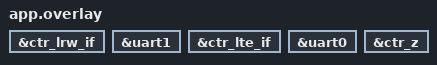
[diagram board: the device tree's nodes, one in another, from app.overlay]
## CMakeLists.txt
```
#
# Copyright (c) 2024 HARDWARIO a.s.
#
#  SPDX-License-Identifier: LicenseRef-HARDWARIO-5-Clause
#

cmake_minimum_required(VERSION 3.20.0)

set(ENV{FW_BUNDLE} "com.hardwario.chester.push")
set(ENV{FW_VERSION} "v1.0.0")
set(ENV{FW_NAME} "CHESTER Push")

find_package(Zephyr REQUIRED HINTS $ENV{ZEPHYR_BASE})

project(chester-push)

add_custom_command(
    COMMAND ../../../scripts/gen-msg-key.py ../codec/cbor-decoder.yaml ../src/msg_key.h
    OUTPUT ../src/msg_key.h
    MAIN_DEPENDENCY ../codec/cbor-decoder.yaml
)

target_sources(app PRIVATE src/app_sensor.c)
target_sources(app PRIVATE src/main.c)
target_sources(app PRIVATE src/app_shell.c)
target_sources(app PRIVATE src/app_init.c)
target_sources(app PRIVATE src/app_data.c)
target_sources(app PRIVATE src/app_power.c)
target_sources(app PRIVATE src/app_send.c)
target_sources(app PRIVATE src/app_config.c)
target_sources(app PRIVATE src/app_work.c)
target_sources(app PRIVATE src/app_handler.c)
target_sources(app PRIVATE src/app_backup.c)
target_sources(app PRIVATE src/app_cbor.c)
```

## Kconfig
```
#
# Copyright (c) 2024 HARDWARIO a.s.
#
# SPDX-License-Identifier: LicenseRef-HARDWARIO-5-Clause
#

menu "Application"

# CHESTER PUSH Project | PUSH Variant 

# LRW 
config SHIELD_CTR_LRW
	bool "Enable SHIELD_CTR_LRW"
	default y 

config CTR_LRW
	default y
# LTE 
config SHIELD_CTR_LTE
	bool "Enable SHIELD_CTR_LTE"
	default y 

config CTR_LTE
	default y
# Z 
config SHIELD_CTR_Z
	bool "Enable SHIELD_CTR_Z"
	default y 

config CTR_Z
	default y

config I2C
	default y

endmenu

menu "Zephyr Kernel"
source "Kconfig.zephyr"
endmenu
```

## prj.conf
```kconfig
#
# Copyright (c) 2024 HARDWARIO a.s.
#
#  SPDX-License-Identifier: LicenseRef-HARDWARIO-5-Clause
#

# Configurations
CONFIG_ADC_SHELL=y
CONFIG_CTR_ACCEL=y
CONFIG_CTR_ADC=y
CONFIG_CTR_BATT=y
CONFIG_CTR_BUTTON=y
CONFIG_CTR_BLE=y
CONFIG_CTR_BUF=y
CONFIG_CTR_DEFAULTS=y
CONFIG_CTR_EDGE=y
CONFIG_CTR_INFO=y
CONFIG_CTR_LED=y
CONFIG_CTR_LOG=y
CONFIG_CTR_RTC=y
CONFIG_CTR_THERM=y
CONFIG_CTR_WDOG=y
CONFIG_ENTROPY_GENERATOR=y
CONFIG_TINYCRYPT=y
CONFIG_TINYCRYPT_SHA256=y
CONFIG_ZCBOR=y
CONFIG_ZCBOR_STOP_ON_ERROR=y
CONFIG_CTR_LTE_CLKSYNC=y

# Extra configurations
CONFIG_ADC_TLA2021_INIT_PRIORITY=60
CONFIG_ADC_SHELL=n
CONFIG_ADC_NRFX_SAADC=n

# USER CODE BEGIN Config 
# USER CODE END Config
```

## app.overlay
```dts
/*
 * Copyright (c) 2024 HARDWARIO a.s.
 *
 * SPDX-License-Identifier: LicenseRef-HARDWARIO-5-Clause
 */

/* CHESTER PUSH Project | PUSH Variant */

/* LRW   */
&ctr_lrw_if {
	status = "okay";
};

&uart1 {
	status = "okay";
};
/* LTE  */
&ctr_lte_if {
	status = "okay";
};

&uart0 {
	status = "okay";
};
/* Z  */
&ctr_z {
	status = "okay";
};
```

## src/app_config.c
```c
/*
 * Copyright (c) 2024 HARDWARIO a.s.
 *
 * SPDX-License-Identifier: LicenseRef-HARDWARIO-5-Clause
 */

#include "app_config.h"

/* CHESTER includes */
#include <chester/ctr_config.h>

/* Zephyr includes */
#include <zephyr/init.h>
#include <zephyr/kernel.h>
#include <zephyr/logging/log.h>
#include <zephyr/settings/settings.h>
#include <zephyr/shell/shell.h>

/* Standard includes */
#include <ctype.h>
#include <stdbool.h>
#include <stdio.h>
#include <stdlib.h>
#include <string.h>

/* USER CODE BEGIN Includes */
/* USER CODE END Includes */

LOG_MODULE_REGISTER(app_config, LOG_LEVEL_DBG);

#define SETTINGS_PFX "chester-push"

struct app_config g_app_config;

static struct app_config m_app_config_interim = {
	.interval_report = 1800,
	.interval_sample = 60,
	.event_report_delay = 5,
	.event_report_rate = 30,
	.backup_report_connected = true,
	.backup_report_disconnected = true,
	.mode = APP_CONFIG_MODE_LTE,

	/* USER CODE BEGIN Struct Variables */
	/* USER CODE END Struct Variables */
};

/* USER CODE BEGIN Variables */
/* USER CODE END Variables */

static void print_app_config_mode(const struct shell *shell)
{
	const char *mode;
	switch (m_app_config_interim.mode) {
	case APP_CONFIG_MODE_NONE:
		mode = "none";
		break;
	case APP_CONFIG_MODE_LTE:
		mode = "lte";
		break;
	case APP_CONFIG_MODE_LRW:
		mode = "lrw";
		break;
	default:
		mode = "(unknown)";
		break;
	}

	shell_print(shell, "app config mode %s", mode);
}

int app_config_cmd_config_mode(const struct shell *shell, size_t argc, char **argv)
{
	if (argc == 1) {
		print_app_config_mode(shell);
		return 0;
	}

	if (argc == 2) {
		if (!strcmp("none", argv[1])) {
			m_app_config_interim.mode = APP_CONFIG_MODE_NONE;
			return 0;
		}

		if (!strcmp("lte", argv[1])) {
			m_app_config_interim.mode = APP_CONFIG_MODE_LTE;
			return 0;
		}

		if (!strcmp("lrw", argv[1])) {
			m_app_config_interim.mode = APP_CONFIG_MODE_LRW;
			return 0;
		}

		shell_error(shell, "invalid option");

		return -EINVAL;
	}

	shell_help(shell);

	return -EINVAL;
}

static void print_interval_report(const struct shell *shell)
{
	shell_print(shell, "app config interval-report  %d",
			m_app_config_interim.interval_report);
}

int app_config_cmd_config_interval_report(const struct shell *shell, size_t argc, char **argv)
{
	if (argc == 1) {
		print_interval_report(shell);
		return 0;
	}
	if (argc == 2) {
		size_t len = strlen(argv[1]);
		for (size_t i = 0; i < len; i++) {
			if (!isdigit((int)argv[1][i])) {
				shell_error(shell, "invalid format");
				return -EINVAL;
			}
		}
		long value = strtol(argv[1], NULL, 10);
		if (value < 30 || value > 86400) {
			shell_error(shell, "invalid range");
			return -EINVAL;
		}
		m_app_config_interim.interval_report = (int)value;
		return 0;
	}
	shell_help(shell);
	return -EINVAL;
}

static void print_interval_sample(const struct shell *shell)
{
	shell_print(shell, "app config interval-sample  %d",
			m_app_config_interim.interval_sample);
}

int app_config_cmd_config_interval_sample(const struct shell *shell, size_t argc, char **argv)
{
	if (argc == 1) {
		print_interval_sample(shell);
		return 0;
	}
	if (argc == 2) {
		size_t len = strlen(argv[1]);
		for (size_t i = 0; i < len; i++) {
			if (!isdigit((int)argv[1][i])) {
				shell_error(shell, "invalid format");
				return -EINVAL;
			}
		}
		long value = strtol(argv[1], NULL, 10);
		if (value < 1 || value > 86400) {
			shell_error(shell, "invalid range");
			return -EINVAL;
		}
		m_app_config_interim.interval_sample = (int)value;
		return 0;
	}
	shell_help(shell);
	return -EINVAL;
}

static void print_event_report_delay(const struct shell *shell)
{
	shell_print(shell, "app config event-report-delay  %d",
			m_app_config_interim.event_report_delay);
}

int app_config_cmd_config_event_report_delay(const struct shell *shell, size_t argc, char **argv)
{
	if (argc == 1) {
		print_event_report_delay(shell);
		return 0;
	}
	if (argc == 2) {
		size_t len = strlen(argv[1]);
		for (size_t i = 0; i < len; i++) {
			if (!isdigit((int)argv[1][i])) {
				shell_error(shell, "invalid format");
				return -EINVAL;
			}
		}
		long value = strtol(argv[1], NULL, 10);
		if (value < 1 || value > 86400) {
			shell_error(shell, "invalid range");
			return -EINVAL;
		}
		m_app_config_interim.event_report_delay = (int)value;
		return 0;
	}
	shell_help(shell);
	return -EINVAL;
}

static void print_event_report_rate(const struct shell *shell)
{
	shell_print(shell, "app config event-report-rate  %d",
			m_app_config_interim.event_report_rate);
}

int app_config_cmd_config_event_report_rate(const struct shell *shell, size_t argc, char **argv)
{
	if (argc == 1) {
		print_event_report_rate(shell);
		return 0;
	}
	if (argc == 2) {
		size_t len = strlen(argv[1]);
		for (size_t i = 0; i < len; i++) {
			if (!isdigit((int)argv[1][i])) {
				shell_error(shell, "invalid format");
				return -EINVAL;
			}
		}
		long value = strtol(argv[1], NULL, 10);
		if (value < 1 || value > 3600) {
			shell_error(shell, "invalid range");
			return -EINVAL;
		}
		m_app_config_interim.event_report_rate = (int)value;
		return 0;
	}
	shell_help(shell);
	return -EINVAL;
}

static void print_backup_report_connected(const struct shell *shell)
{
	shell_print(shell, "app config backup-report-connected  %s",
			m_app_config_interim.backup_report_connected ? "true" : "false");
}

int app_config_cmd_config_backup_report_connected(const struct shell *shell, size_t argc, char **argv)
{
	if (argc == 1) {
		print_backup_report_connected(shell);                                                    
		return 0;
	}
	if (argc == 2) {
		bool is_false = !strcmp(argv[1], "false");
		bool is_true = !strcmp(argv[1], "true");
		if (is_false) {
			m_app_config_interim.backup_report_connected = false;
		} else if (is_true) {
			m_app_config_interim.backup_report_connected = true;
		} else {
			shell_error(shell, "invalid format");
			return -EINVAL;
		}
		return 0;
	}
	shell_help(shell);
	return -EINVAL;
}

static void print_backup_report_disconnected(const struct shell *shell)
{
	shell_print(shell, "app config backup-report-disconnected  %s",
			m_app_config_interim.backup_report_disconnected ? "true" : "false");
}

int app_config_cmd_config_backup_report_disconnected(const struct shell *shell, size_t argc, char **argv)
{
	if (argc == 1) {
		print_backup_report_disconnected(shell);                                                    
		return 0;
	}
	if (argc == 2) {
		bool is_false = !strcmp(argv[1], "false");
		bool is_true = !strcmp(argv[1], "true");
		if (is_false) {
			m_app_config_interim.backup_report_disconnected = false;
		} else if (is_true) {
			m_app_config_interim.backup_report_disconnected = true;
		} else {
			shell_error(shell, "invalid format");
			return -EINVAL;
		}
		return 0;
	}
	shell_help(shell);
	return -EINVAL;
}

int app_config_cmd_config_show(const struct shell *shell, size_t argc, char **argv)
{
	print_app_config_mode(shell);
	print_interval_report(shell);
	print_interval_sample(shell);
	print_event_report_delay(shell);
	print_event_report_rate(shell);
	print_backup_report_connected(shell);
	print_backup_report_disconnected(shell);
	
	return 0;
}

/* USER CODE BEGIN Functions 1 */
/* USER CODE END Functions 1 */

static int h_commit(void)
{
	LOG_DBG("Loaded settings in full");
	memcpy(&g_app_config, &m_app_config_interim, sizeof(g_app_config));

	return 0;
}

static int h_set(const char *key, size_t len, settings_read_cb read_cb, void *cb_arg) 
{
	int ret;
	const char *next;
	if (settings_name_steq(key, "mode", &next) && !next) {
		if (len != sizeof(m_app_config_interim.mode)) {
			return -EINVAL;
		}
		ret = read_cb(cb_arg, &m_app_config_interim.mode, len);
		if (ret < 0) {
			LOG_ERR("Call `read_cb` failed: %d", ret);
			return ret;
		}
		return 0;
	}
	
	if (settings_name_steq(key, "interval-report", &next) && !next) {
		if (len != sizeof(m_app_config_interim.interval_report)) {
			return -EINVAL;
		}
		ret = read_cb(cb_arg, &m_app_config_interim.interval_report, len);
		if (ret < 0) {
			LOG_ERR("Call `read_cb` failed: %d", ret);
			return ret;
		}
		return 0;
	}

	if (settings_name_steq(key, "interval-sample", &next) && !next) {
		if (len != sizeof(m_app_config_interim.interval_sample)) {
			return -EINVAL;
		}
		ret = read_cb(cb_arg, &m_app_config_interim.interval_sample, len);
		if (ret < 0) {
			LOG_ERR("Call `read_cb` failed: %d", ret);
			return ret;
		}
		return 0;
	}

	if (settings_name_steq(key, "event-report-delay", &next) && !next) {
		if (len != sizeof(m_app_config_interim.event_report_delay)) {
			return -EINVAL;
		}
		ret = read_cb(cb_arg, &m_app_config_interim.event_report_delay, len);
		if (ret < 0) {
			LOG_ERR("Call `read_cb` failed: %d", ret);
			return ret;
		}
		return 0;
	}

	if (settings_name_steq(key, "event-report-rate", &next) && !next) {
		if (len != sizeof(m_app_config_interim.event_report_rate)) {
			return -EINVAL;
		}
		ret = read_cb(cb_arg, &m_app_config_interim.event_report_rate, len);
		if (ret < 0) {
			LOG_ERR("Call `read_cb` failed: %d", ret);
			return ret;
		}
		return 0;
	}

	if (settings_name_steq(key, "backup-report-connected", &next) && !next) {
		if (len != sizeof(m_app_config_interim.backup_report_connected)) {
			return -EINVAL;
		}
		ret = read_cb(cb_arg, &m_app_config_interim.backup_report_connected, len);
		if (ret < 0) {
			LOG_ERR("Call `read_cb` failed: %d", ret);
			return ret;
		}
		return 0;
	}

	if (settings_name_steq(key, "backup-report-disconnected", &next) && !next) {
		if (len != sizeof(m_app_config_interim.backup_report_disconnected)) {
			return -EINVAL;
		}
		ret = read_cb(cb_arg, &m_app_config_interim.backup_report_disconnected, len);
		if (ret < 0) {
			LOG_ERR("Call `read_cb` failed: %d", ret);
			return ret;
		}
		return 0;
	}

	/* USER CODE BEGIN Functions 2 */
	/* USER CODE END Functions 2 */

	return 0;
}

static int h_export(int (*export_func)(const char *name, const void *val, size_t val_len))
{
	int ret;
	ret = export_func("chester-push/mode", &m_app_config_interim.mode,
					  sizeof( m_app_config_interim.mode));
	if (ret < 0) {
		return ret;
	}

	ret = export_func("chester-push/interval-report", &m_app_config_interim.interval_report,
					  sizeof( m_app_config_interim.interval_report));
	if (ret < 0) {
		return ret;
	}

	ret = export_func("chester-push/interval-sample", &m_app_config_interim.interval_sample,
					  sizeof( m_app_config_interim.interval_sample));
	if (ret < 0) {
		return ret;
	}

	ret = export_func("chester-push/event-report-delay", &m_app_config_interim.event_report_delay,
					  sizeof( m_app_config_interim.event_report_delay));
	if (ret < 0) {
		return ret;
	}

	ret = export_func("chester-push/event-report-rate", &m_app_config_interim.event_report_rate,
					  sizeof( m_app_config_interim.event_report_rate));
	if (ret < 0) {
		return ret;
	}

	ret = export_func("chester-push/backup-report-connected", &m_app_config_interim.backup_report_connected,
					  sizeof( m_app_config_interim.backup_report_connected));
	if (ret < 0) {
		return ret;
	}

	ret = export_func("chester-push/backup-report-disconnected", &m_app_config_interim.backup_report_disconnected,
					  sizeof( m_app_config_interim.backup_report_disconnected));
	if (ret < 0) {
		return ret;
	}

	/* USER CODE BEGIN Functions 3 */
	/* USER CODE END Functions 3 */

	return 0;
}

static int init(void) 
{
	int ret;

	LOG_INF("System initialization");

	static struct settings_handler sh = {
		.name = SETTINGS_PFX,
		.h_set = h_set,
		.h_commit = h_commit,
		.h_export = h_export,
	};

	ret = settings_register(&sh);

	if (ret < 0) {
		LOG_ERR("Call `settings_register` failed: %d", ret);
		return ret;
	}

	ret = settings_load_subtree(SETTINGS_PFX);

	if (ret < 0) {
		LOG_ERR("Call `settings_load_subtree` failed: %d", ret);
		return ret;
	}

	ctr_config_append_show(SETTINGS_PFX, app_config_cmd_config_show);

	/* USER CODE BEGIN Functions 4 */
	/* USER CODE END Functions 4 */

	return 0;
}

SYS_INIT(init, APPLICATION, CONFIG_APPLICATION_INIT_PRIORITY);
```

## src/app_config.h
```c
/*
 * Copyright (c) 2024 HARDWARIO a.s.
 *
 * SPDX-License-Identifier: LicenseRef-HARDWARIO-5-Clause
 */

#ifndef APP_CONFIG_H_
#define APP_CONFIG_H_

/* Zephyr includes */
#include <zephyr/shell/shell.h>

/* Standard includes */
#include <stdbool.h>
#include <stddef.h>

/* USER CODE BEGIN Includes */
/* USER CODE END Includes */

#ifdef __cplusplus
extern "C" {
#endif

enum app_config_mode {
	APP_CONFIG_MODE_NONE = 0,
	APP_CONFIG_MODE_LTE = 1,
	APP_CONFIG_MODE_LRW = 2,
};

struct app_config {
	enum app_config_mode mode;
	int interval_report;
	int interval_sample;
	int event_report_delay;
	int event_report_rate;
	bool backup_report_connected;
	bool backup_report_disconnected;

	/* USER CODE BEGIN Struct Variables */
	/* USER CODE END Struct Variables */
};

extern struct app_config g_app_config;

/* USER CODE BEGIN Variables */
/* USER CODE END Variables */

int app_config_cmd_config_mode(const struct shell *shell, size_t argc, char **argv);
int app_config_cmd_config_show(const struct shell *shell, size_t argc, char **argv);
int app_config_cmd_config_interval_report(const struct shell *shell, size_t argc, char **argv);
int app_config_cmd_config_interval_sample(const struct shell *shell, size_t argc, char **argv);
int app_config_cmd_config_event_report_delay(const struct shell *shell, size_t argc, char **argv);
int app_config_cmd_config_event_report_rate(const struct shell *shell, size_t argc, char **argv);
int app_config_cmd_config_backup_report_connected(const struct shell *shell, size_t argc, char **argv);
int app_config_cmd_config_backup_report_disconnected(const struct shell *shell, size_t argc, char **argv);

/* USER CODE BEGIN Functions 1 */
/* USER CODE END Functions 1 */

#ifdef __cplusplus
}
#endif

#endif /* APP_CONFIG_H_ */
```

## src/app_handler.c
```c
/*
 * Copyright (c) 2023 HARDWARIO a.s.
 *
 * SPDX-License-Identifier: LicenseRef-HARDWARIO-5-Clause
 */

#include "app_backup.h"
#include "app_config.h"
#include "app_data.h"
#include "app_handler.h"
#include "app_init.h"
#include "app_work.h"

/* CHESTER includes */
#include <chester/ctr_led.h>
#include <chester/ctr_lrw.h>
#include <chester/ctr_lte.h>
#include <chester/ctr_rtc.h>
#include <chester/drivers/ctr_z.h>

/* Zephyr includes */
#include <zephyr/device.h>
#include <zephyr/devicetree.h>
#include <zephyr/kernel.h>
#include <zephyr/logging/log.h>
#include <zephyr/sys/reboot.h>

/* Standard includes */
#include <inttypes.h>
#include <math.h>
#include <stdbool.h>
#include <stddef.h>

LOG_MODULE_REGISTER(app_handler, LOG_LEVEL_DBG);

#if defined(CONFIG_SHIELD_CTR_Z)
static atomic_t m_report_rate_hourly_counter = 0;
static atomic_t m_report_rate_timer_is_active = false;
static atomic_t m_report_delay_timer_is_active = false;
#endif /* defined(CONFIG_SHIELD_CTR_Z) */

static void start(void)
{
	int ret;

	ret = ctr_lte_start(NULL);
	if (ret) {
		LOG_ERR("Call `ctr_lte_start` failed: %d", ret);
		k_oops();
	}
}

static void attach(void)
{
	int ret;

	ret = ctr_lte_attach(NULL);
	if (ret) {
		LOG_ERR("Call `ctr_lte_attach` failed: %d", ret);
		k_oops();
	}
}

void app_handler_lrw(enum ctr_lrw_event event, union ctr_lrw_event_data *data, void *param)
{
	int ret;

	switch (event) {
	case CTR_LRW_EVENT_FAILURE:
		LOG_INF("Event `CTR_LRW_EVENT_FAILURE`");
		ret = ctr_lrw_start(NULL);
		if (ret) {
			LOG_ERR("Call `ctr_lrw_start` failed: %d", ret);
		}
		break;
	case CTR_LRW_EVENT_START_OK:
		LOG_INF("Event `CTR_LRW_EVENT_START_OK`");
		ret = ctr_lrw_join(NULL);
		if (ret) {
			LOG_ERR("Call `ctr_lrw_join` failed: %d", ret);
		}
		break;
	case CTR_LRW_EVENT_START_ERR:
		LOG_INF("Event `CTR_LRW_EVENT_START_ERR`");
		break;
	case CTR_LRW_EVENT_JOIN_OK:
		LOG_INF("Event `CTR_LRW_EVENT_JOIN_OK`");
		break;
	case CTR_LRW_EVENT_JOIN_ERR:
		LOG_INF("Event `CTR_LRW_EVENT_JOIN_ERR`");
		break;
	case CTR_LRW_EVENT_SEND_OK:
		LOG_INF("Event `CTR_LRW_EVENT_SEND_OK`");
		break;
	case CTR_LRW_EVENT_SEND_ERR:
		LOG_INF("Event `CTR_LRW_EVENT_SEND_ERR`");
		break;
	default:
		LOG_WRN("Unknown event: %d", event);
	}
}

void app_handler_lte(enum ctr_lte_event event, union ctr_lte_event_data *data, void *param)
{
	switch (event) {
	case CTR_LTE_EVENT_FAILURE:
		LOG_ERR("Event `CTR_LTE_EVENT_FAILURE`");
		start();
		break;

	case CTR_LTE_EVENT_START_OK:
		LOG_INF("Event `CTR_LTE_EVENT_START_OK`");
		attach();
		break;

	case CTR_LTE_EVENT_START_ERR:
		LOG_ERR("Event `CTR_LTE_EVENT_START_ERR`");
		start();
		break;

	case CTR_LTE_EVENT_ATTACH_OK:
		LOG_INF("Event `CTR_LTE_EVENT_ATTACH_OK`");
		k_sem_give(&g_app_init_sem);
		break;

	case CTR_LTE_EVENT_ATTACH_ERR:
		LOG_ERR("Event `CTR_LTE_EVENT_ATTACH_ERR`");
		start();
		break;

	case CTR_LTE_EVENT_DETACH_OK:
		LOG_INF("Event `CTR_LTE_EVENT_DETACH_OK`");
		break;

	case CTR_LTE_EVENT_DETACH_ERR:
		LOG_ERR("Event `CTR_LTE_EVENT_DETACH_ERR`");
		start();
		break;

	case CTR_LTE_EVENT_EVAL_OK:
		LOG_INF("Event `CTR_LTE_EVENT_EVAL_OK`");

		struct ctr_lte_eval *eval = &data->eval_ok.eval;

		LOG_DBG("EEST: %d", eval->eest);
		LOG_DBG("ECL: %d", eval->ecl);
		LOG_DBG("RSRP: %d", eval->rsrp);
		LOG_DBG("RSRQ: %d", eval->rsrq);
		LOG_DBG("SNR: %d", eval->snr);
		LOG_DBG("PLMN: %d", eval->plmn);
		LOG_DBG("CID: %d", eval->cid);
		LOG_DBG("BAND: %d", eval->band);
		LOG_DBG("EARFCN: %d", eval->earfcn);

		k_mutex_lock(&g_app_data_lte_eval_mut, K_FOREVER);
		memcpy(&g_app_data_lte_eval, &data->eval_ok.eval, sizeof(g_app_data_lte_eval));
		g_app_data_lte_eval_valid = true;
		k_mutex_unlock(&g_app_data_lte_eval_mut);

		break;

	case CTR_LTE_EVENT_EVAL_ERR:
		LOG_ERR("Event `CTR_LTE_EVENT_EVAL_ERR`");

		k_mutex_lock(&g_app_data_lte_eval_mut, K_FOREVER);
		g_app_data_lte_eval_valid = false;
		k_mutex_unlock(&g_app_data_lte_eval_mut);

		break;

	case CTR_LTE_EVENT_SEND_OK:
		LOG_INF("Event `CTR_LTE_EVENT_SEND_OK`");
		break;

	case CTR_LTE_EVENT_SEND_ERR:
		LOG_ERR("Event `CTR_LTE_EVENT_SEND_ERR`");
		start();
		break;

	default:
		LOG_WRN("Unknown event: %d", event);
		return;
	}
}

#if defined(CONFIG_SHIELD_CTR_Z)

static void report_delay_timer_handler(struct k_timer *timer)
{
	app_work_send();
	atomic_inc(&m_report_rate_hourly_counter);
	atomic_set(&m_report_delay_timer_is_active, false);
}

static K_TIMER_DEFINE(m_report_delay_timer, report_delay_timer_handler, NULL);

static void report_rate_timer_handler(struct k_timer *timer)
{
	atomic_set(&m_report_rate_hourly_counter, 0);
	atomic_set(&m_report_rate_timer_is_active, false);
}

static K_TIMER_DEFINE(m_report_rate_timer, report_rate_timer_handler, NULL);

static void send_with_rate_limit(void)
{
	if (!atomic_get(&m_report_rate_timer_is_active)) {
		k_timer_start(&m_report_rate_timer, K_HOURS(1), K_NO_WAIT);
		atomic_set(&m_report_rate_timer_is_active, true);
	}

	LOG_INF("Hourly counter state: %d/%d", (int)atomic_get(&m_report_rate_hourly_counter),
		g_app_config.event_report_rate);

	if (atomic_get(&m_report_rate_hourly_counter) <= g_app_config.event_report_rate) {
		if (!atomic_get(&m_report_delay_timer_is_active)) {
			LOG_INF("Starting delay timer");
			k_timer_start(&m_report_delay_timer,
				      K_SECONDS(g_app_config.event_report_delay), K_NO_WAIT);
			atomic_set(&m_report_delay_timer_is_active, true);
		} else {
			LOG_INF("Delay timer already running");
		}
	} else {
		LOG_WRN("Hourly counter exceeded");
	}
}

void handle_dc_event(enum ctr_z_event backup_event)
{
	int ret;

	struct app_data_backup *backup = &g_app_data.backup;

	app_data_lock();

	backup->line_present = backup_event == CTR_Z_EVENT_DC_CONNECTED;

	if (backup->event_count < APP_DATA_MAX_BACKUP_EVENTS) {
		struct app_data_backup_event *event = &backup->events[backup->event_count];

		ret = ctr_rtc_get_ts(&event->timestamp);
		if (ret) {
			LOG_ERR("Call `ctr_rtc_get_ts` failed: %d", ret);
			app_data_unlock();
			return;
		}

		event->connected = backup->line_present;
		backup->event_count++;

		LOG_INF("Event count: %d", backup->event_count);
	} else {
		LOG_WRN("Measurement full");
		app_data_unlock();
		return;
	}

	LOG_INF("Backup: %d", (int)backup->line_present);

	if (g_app_config.backup_report_connected && backup_event == CTR_Z_EVENT_DC_CONNECTED) {
		send_with_rate_limit();
	}

	if (g_app_config.backup_report_disconnected &&
	    backup_event == CTR_Z_EVENT_DC_DISCONNECTED) {
		send_with_rate_limit();
	}

	app_data_unlock();
}

#if defined(CONFIG_APP_FLIP_MODE)
static int handle_button(enum ctr_z_event event, enum ctr_z_event match,
			 enum ctr_z_led_channel led_channel,
			 enum ctr_z_buzzer_command buzzer_command,
			 enum app_data_button_event_type button_event,
			 struct app_data_button *button)
#else
static int handle_button(enum ctr_z_event event, enum ctr_z_event match,
			 enum ctr_z_led_channel led_channel, enum ctr_z_led_command led_command,
			 enum ctr_z_buzzer_command buzzer_command,
			 enum app_data_button_event_type button_event,
			 struct app_data_button *button)
#endif /* defined(CONFIG_APP_FLIP_MODE) */
{
	int ret;

	if (event != match) {
		return 0;
	}

	static const struct device *dev = DEVICE_DT_GET(DT_NODELABEL(ctr_z));

	if (!device_is_ready(dev)) {
		LOG_ERR("Device not ready");
		return -ENODEV;
	}

	struct ctr_z_led_param led_param = {
		.brightness = CTR_Z_LED_BRIGHTNESS_HIGH,
#if defined(CONFIG_APP_FLIP_MODE)
		.command = CTR_Z_LED_COMMAND_NONE,
		.pattern = CTR_Z_LED_PATTERN_ON,
#else
		.command = led_command,
		.pattern = CTR_Z_LED_PATTERN_OFF,
#endif /* defined(CONFIG_APP_FLIP_MODE) */
	};

	ret = ctr_z_set_led(dev, led_channel, &led_param);
	if (ret) {
		LOG_ERR("Call `ctr_z_set_led` failed: %d", ret);
		return ret;
	}

	struct ctr_z_buzzer_param buzzer_param = {
		.command = buzzer_command,
		.pattern = CTR_Z_BUZZER_PATTERN_OFF,
	};

	ret = ctr_z_set_buzzer(dev, &buzzer_param);
	if (ret) {
		LOG_ERR("Call `ctr_z_set_buzzer` failed: %d", ret);
		return ret;
	}

	bool button_event_type_is_click = true;

	if (event == CTR_Z_EVENT_BUTTON_0_HOLD || event == CTR_Z_EVENT_BUTTON_1_HOLD ||
	    event == CTR_Z_EVENT_BUTTON_2_HOLD || event == CTR_Z_EVENT_BUTTON_3_HOLD ||
	    event == CTR_Z_EVENT_BUTTON_4_HOLD) {
		button_event_type_is_click = false;
	}

	app_data_lock();

	if (button->event_count < APP_DATA_MAX_BUTTON_EVENTS) {
		struct app_data_button_event *event = &button->events[button->event_count];

		ret = ctr_rtc_get_ts(&event->timestamp);
		if (ret) {
			LOG_ERR("Call `ctr_rtc_get_ts` failed: %d", ret);
			app_data_unlock();
			return ret;
		}

		event->type = button_event_type_is_click ? 0 : 1;
		button->event_count++;

		LOG_INF("Event count: %d", button->event_count);
		LOG_INF("Button event: %d", button_event);
	} else {
		LOG_WRN("Event full");
		app_data_unlock();
		return -ENOSPC;
	}

	if (button_event_type_is_click) {
		atomic_inc(&button->click_count);
	} else {
		atomic_inc(&button->hold_count);
	}

	app_data_unlock();

	send_with_rate_limit();

	return 1;
}

void app_handler_ctr_z(const struct device *dev, enum ctr_z_event event, void *user_data)
{
	int ret;

	LOG_INF("Event: %d", event);

#if defined(CONFIG_APP_FLIP_MODE)

#define CLEAR_LED(button)                                                                          \
	do {                                                                                       \
		struct ctr_z_led_param led_param = {                                               \
			.brightness = CTR_Z_LED_BRIGHTNESS_OFF,                                    \
			.command = CTR_Z_LED_COMMAND_NONE,                                         \
			.pattern = CTR_Z_LED_PATTERN_OFF,                                          \
		};                                                                                 \
		ret = ctr_z_set_led(dev, CTR_Z_LED_CHANNEL_##button##_R, &led_param);              \
		if (ret) {                                                                         \
			LOG_ERR("Call `ctr_z_set_led` failed: %d", ret);                           \
		}                                                                                  \
	} while (0)

	if (event == CTR_Z_EVENT_BUTTON_0_PRESS || event == CTR_Z_EVENT_BUTTON_1_PRESS ||
	    event == CTR_Z_EVENT_BUTTON_2_PRESS || event == CTR_Z_EVENT_BUTTON_3_PRESS ||
	    event == CTR_Z_EVENT_BUTTON_4_PRESS) {
		CLEAR_LED(0);
		CLEAR_LED(1);
		CLEAR_LED(2);
		CLEAR_LED(3);
		CLEAR_LED(4);
	}

#undef CLEAR_LED

#define HANDLE_PRESS(button_index, button_event)                                                   \
	do {                                                                                       \
		ret = handle_button(event, CTR_Z_EVENT_BUTTON_##button_index##_PRESS,              \
				    CTR_Z_LED_CHANNEL_##button_index##_R,                          \
				    CTR_Z_BUZZER_COMMAND_1X_1_2, button_event,                     \
				    &g_app_data.button[button_index]);                             \
		if (ret < 0) {                                                                     \
			LOG_ERR("Call `handle_button` failed: %d", ret);                           \
		} else if (ret) {                                                                  \
			goto apply;                                                                \
		}                                                                                  \
	} while (0)

	HANDLE_PRESS(0, APP_DATA_BUTTON_EVENT_X_CLICK);
	HANDLE_PRESS(1, APP_DATA_BUTTON_EVENT_1_CLICK);
	HANDLE_PRESS(2, APP_DATA_BUTTON_EVENT_2_CLICK);
	HANDLE_PRESS(3, APP_DATA_BUTTON_EVENT_3_CLICK);
	HANDLE_PRESS(4, APP_DATA_BUTTON_EVENT_4_CLICK);

#undef HANDLE_PRESS

#else

#define HANDLE_CLICK(button_index, button_event)                                                   \
	do {                                                                                       \
		ret = handle_button(event, CTR_Z_EVENT_BUTTON_##button_index##_CLICK,              \
				    CTR_Z_LED_CHANNEL_##button_index##_G,                          \
				    CTR_Z_LED_COMMAND_1X_1_2, CTR_Z_BUZZER_COMMAND_1X_1_2,         \
				    button_event, &g_app_data.button[button_index]);               \
		if (ret < 0) {                                                                     \
			LOG_ERR("Call `handle_button` failed: %d", ret);                           \
		} else if (ret) {                                                                  \
			goto apply;                                                                \
		}                                                                                  \
	} while (0)

	HANDLE_CLICK(0, APP_DATA_BUTTON_EVENT_X_CLICK);
	HANDLE_CLICK(1, APP_DATA_BUTTON_EVENT_1_CLICK);
	HANDLE_CLICK(2, APP_DATA_BUTTON_EVENT_2_CLICK);
	HANDLE_CLICK(3, APP_DATA_BUTTON_EVENT_3_CLICK);
	HANDLE_CLICK(4, APP_DATA_BUTTON_EVENT_4_CLICK);

#undef HANDLE_CLICK

#define HANDLE_HOLD(button_index, button_event)                                                    \
	do {                                                                                       \
		ret = handle_button(event, CTR_Z_EVENT_BUTTON_##button_index##_HOLD,               \
				    CTR_Z_LED_CHANNEL_##button_index##_R,                          \
				    CTR_Z_LED_COMMAND_2X_1_2, CTR_Z_BUZZER_COMMAND_2X_1_2,         \
				    button_event, &g_app_data.button[button_index]);               \
		if (ret < 0) {                                                                     \
			LOG_ERR("Call `handle_button` failed: %d", ret);                           \
		} else if (ret) {                                                                  \
			goto apply;                                                                \
		}                                                                                  \
	} while (0)

	HANDLE_HOLD(0, APP_DATA_BUTTON_EVENT_X_HOLD);
	HANDLE_HOLD(1, APP_DATA_BUTTON_EVENT_1_HOLD);
	HANDLE_HOLD(2, APP_DATA_BUTTON_EVENT_2_HOLD);
	HANDLE_HOLD(3, APP_DATA_BUTTON_EVENT_3_HOLD);
	HANDLE_HOLD(4, APP_DATA_BUTTON_EVENT_4_HOLD);

#undef HANDLE_HOLD

#endif /* defined(CONFIG_APP_FLIP_MODE) */

	switch (event) {
	case CTR_Z_EVENT_DEVICE_RESET:
		LOG_INF("Event `CTR_Z_EVENT_DEVICE_RESET`");
		goto apply;

	case CTR_Z_EVENT_DC_CONNECTED:
		LOG_INF("Event `CTR_Z_EVENT_DC_CONNECTED`");
		app_work_backup_update();
		handle_dc_event(event);
		break;

	case CTR_Z_EVENT_DC_DISCONNECTED:
		LOG_INF("Event `CTR_Z_EVENT_DC_DISCONNECTED`");
		app_work_backup_update();
		handle_dc_event(event);
		break;
	default:
		break;
	}

apply:
	ret = ctr_z_apply(dev);
	if (ret) {
		LOG_ERR("Call `ctr_z_apply` failed: %d", ret);
	}
}

#endif /* defined(CONFIG_SHIELD_CTR_Z) */

#if defined(CONFIG_CTR_BUTTON)

static void app_load_timer_handler(struct k_timer *timer)
{
	ctr_led_set(CTR_LED_CHANNEL_LOAD, 0);
}

K_TIMER_DEFINE(app_load_timer, app_load_timer_handler, NULL);

void app_handler_ctr_button(enum ctr_button_channel chan, enum ctr_button_event ev, int val,
			    void *user_data)
{
	int ret;

	if (chan != CTR_BUTTON_CHANNEL_INT) {
		return;
	}

	if (ev == CTR_BUTTON_EVENT_CLICK) {
		for (int i = 0; i < val; i++) {
			ret = ctr_led_set(CTR_LED_CHANNEL_Y, true);
			if (ret) {
				LOG_ERR("Call `ctr_led_set` failed: %d", ret);
				return;
			}

			k_sleep(K_MSEC(50));
			ret = ctr_led_set(CTR_LED_CHANNEL_Y, false);
			if (ret) {
				LOG_ERR("Call `ctr_led_set` failed: %d", ret);
				return;
			}

			k_sleep(K_MSEC(200));
		}

		switch (val) {
		case 1:
			app_work_send();
			break;
		case 2:
			app_work_sample();
			break;
		case 3:
			app_work_sample();
			app_work_send();
			break;
		case 4:
			sys_reboot(SYS_REBOOT_COLD);
			break;
		case 5:
			ret = ctr_led_set(CTR_LED_CHANNEL_LOAD, 1);
			if (ret) {
				LOG_ERR("Call `ctr_led_set` failed: %d", ret);
				return;
			}
			k_timer_start(&app_load_timer, K_MINUTES(2), K_FOREVER);
			break;
		}
	}
}

#endif /* defined(CONFIG_CTR_BUTTON) */
```

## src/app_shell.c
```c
/*
 * Copyright (c) 2024 HARDWARIO a.s.
 *
 * SPDX-License-Identifier: LicenseRef-HARDWARIO-5-Clause
 */

#include "app_config.h"
#include "app_work.h"

/* Zephyr includes */
#include <zephyr/kernel.h>
#include <zephyr/logging/log.h>
#include <zephyr/shell/shell.h>

/* Standard includes */
#include <errno.h>
#include <stdlib.h>

/* USER CODE BEGIN Includes */
/* USER CODE END Includes */

LOG_MODULE_REGISTER(app_shell, LOG_LEVEL_INF);

static int cmd_sample(const struct shell *shell, size_t argc, char **argv)
{
	if (argc > 1) {
		shell_error(shell, "unknown parameter: %s", argv[1]);
		shell_help(shell);
		return -EINVAL;
	}

	app_work_sample();

	return 0;
}

static int cmd_send(const struct shell *shell, size_t argc, char **argv)
{
	if (argc > 1) {
		shell_error(shell, "unknown parameter: %s", argv[1]);
		shell_help(shell);
		return -EINVAL;
	}

	app_work_send();

	return 0;
}

static int print_help(const struct shell *shell, size_t argc, char **argv)
{
	if (argc > 1) {
		shell_error(shell, "command not found: %s", argv[1]);
		shell_help(shell);
		return -EINVAL;
	}

	shell_help(shell);
	return 0;
}

/* clang-format off */

SHELL_STATIC_SUBCMD_SET_CREATE(
	sub_app_config,
   
	SHELL_CMD_ARG(show, NULL,
				  "List current configuration.",
				  app_config_cmd_config_show, 1, 0),
	
	SHELL_CMD_ARG(mode, NULL,
				  "Get/Set communication mode (None/LTE/LoRaWAN) ('none', 'lte', 'lrw').",
				  app_config_cmd_config_mode, 1, 1),
	
	SHELL_CMD_ARG(interval-report, NULL,
				  "Get/Set report interval in seconds (format: <30-86400>).",
				  app_config_cmd_config_interval_report, 1, 1),
	
	SHELL_CMD_ARG(interval-sample, NULL,
				  "Get/Set sample interval in seconds (format: <1-86400>).",
				  app_config_cmd_config_interval_sample, 1, 1),
	
	SHELL_CMD_ARG(event-report-delay, NULL,
				  "Get/Set event report delay in seconds (format: <1-86400>).",
				  app_config_cmd_config_event_report_delay, 1, 1),
	
	SHELL_CMD_ARG(event-report-rate, NULL,
				  "Get/Set event report rate in reports per hour (format: <1-3600>).",
				  app_config_cmd_config_event_report_rate, 1, 1),
	
	SHELL_CMD_ARG(backup-report-connected, NULL,
				  "Get/Set report when backup is active (format: true, false).",
				  app_config_cmd_config_backup_report_connected, 1, 1),
	
	SHELL_CMD_ARG(backup-report-disconnected, NULL,
				  "Get/Set report when backup is inactive (format: true, false).",
				  app_config_cmd_config_backup_report_disconnected, 1, 1),
	
	/* USER CODE BEGIN Functions 1 */
	/* USER CODE END Functions 1 */

	SHELL_SUBCMD_SET_END
);

SHELL_STATIC_SUBCMD_SET_CREATE(
	sub_app,

	SHELL_CMD_ARG(config, &sub_app_config, "Configuration commands.",
				  print_help, 1, 0),
		
	SHELL_SUBCMD_SET_END

	/* USER CODE BEGIN Functions 2 */
	/* USER CODE END Functions 2 */
);

SHELL_CMD_REGISTER(app, &sub_app, "Application commands.", print_help);

SHELL_CMD_REGISTER(sample, NULL,"Sample immediately.", cmd_sample);
SHELL_CMD_REGISTER(send, NULL,"Send data immediately.", cmd_send);

/* USER CODE BEGIN Functions 3 */
/* USER CODE END Functions 3 */

/* clang-format on */
```

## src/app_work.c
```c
/*
 * Copyright (c) 2023 HARDWARIO a.s.
 *
 * SPDX-License-Identifier: LicenseRef-HARDWARIO-5-Clause
 */

#include "app_backup.h"
#include "app_config.h"
#include "app_init.h"
#include "app_power.h"
#include "app_send.h"
#include "app_sensor.h"
#include "app_work.h"

/* Zephyr includes */
#include <zephyr/device.h>
#include <zephyr/kernel.h>
#include <zephyr/logging/log.h>
#include <zephyr/random/rand32.h>

/* Standard includes */
#include <math.h>
#include <stddef.h>
#include <stdint.h>

LOG_MODULE_REGISTER(app_work, LOG_LEVEL_DBG);

#define WORK_Q_STACK_SIZE 4096
#define WORK_Q_PRIORITY   K_LOWEST_APPLICATION_THREAD_PRIO

static struct k_work_q m_work_q;
static K_THREAD_STACK_DEFINE(m_work_q_stack, WORK_Q_STACK_SIZE);

static struct k_timer m_send_timer;

static void send_work_handler(struct k_work *work)
{
	int ret;

	int64_t jitter = (int32_t)sys_rand32_get() % (g_app_config.interval_report * 1000 / 5);
	int64_t duration = g_app_config.interval_report * 1000 + jitter;

	LOG_INF("Scheduling next timeout in %lld second(s)", duration / 1000);

	k_timer_start(&m_send_timer, K_MSEC(duration), K_FOREVER);

	ret = app_send();
	if (ret) {
		LOG_ERR("Call `app_send` failed: %d", ret);
	}

#if defined(CONFIG_SHIELD_CTR_Z)
	app_backup_clear();
#endif /* defined(CONFIG_SHIELD_CTR_Z) */
}

static K_WORK_DEFINE(m_send_work, send_work_handler);

static void send_timer_handler(struct k_timer *timer)
{
	int ret;

	ret = k_work_submit_to_queue(&m_work_q, &m_send_work);
	if (ret < 0) {
		LOG_ERR("Call `k_work_submit_to_queue` failed: %d", ret);
	}
}

static K_TIMER_DEFINE(m_send_timer, send_timer_handler, NULL);

static void sample_work_handler(struct k_work *work)
{
	int ret;

#if defined(CONFIG_SHIELD_CTR_Z)
	ret = app_backup_sample();
	if (ret) {
		LOG_ERR("Call `app_backup_sample` failed: %d", ret);
	}
#endif /* defined(CONFIG_SHIELD_CTR_Z) */

	ret = app_sensor_sample();
	if (ret < 0) {
		LOG_ERR("Call `app_sensor_sample` failed: %d", ret);
	}
}

static K_WORK_DEFINE(m_sample_work, sample_work_handler);

static void sample_timer_handler(struct k_timer *timer)
{
	int ret;

	ret = k_work_submit_to_queue(&m_work_q, &m_sample_work);
	if (ret < 0) {
		LOG_ERR("Call `k_work_submit_to_queue` failed: %d", ret);
	}
}

static K_TIMER_DEFINE(m_sample_timer, sample_timer_handler, NULL);

static void power_work_handler(struct k_work *work)
{
	int ret;

	ret = app_power_sample();
	if (ret < 0) {
		LOG_ERR("Call `app_power_sample` failed: %d", ret);
	}
}

static K_WORK_DEFINE(m_power_work, power_work_handler);

static void power_timer_handler(struct k_timer *timer)
{
	int ret;

	ret = k_work_submit_to_queue(&m_work_q, &m_power_work);
	if (ret < 0) {
		LOG_ERR("Call `k_work_submit_to_queue` failed: %d", ret);
	}
}

static K_TIMER_DEFINE(m_power_timer, power_timer_handler, NULL);

int app_work_init(void)
{
	k_work_queue_start(&m_work_q, m_work_q_stack, K_THREAD_STACK_SIZEOF(m_work_q_stack),
			   WORK_Q_PRIORITY, NULL);

	k_thread_name_set(&m_work_q.thread, "APP_WORK");

	/* Delay first report so ctr_z updates line_present */
	k_timer_start(&m_send_timer, K_SECONDS(2), K_FOREVER);
	k_timer_start(&m_sample_timer, K_NO_WAIT, K_SECONDS(g_app_config.interval_sample));
	k_timer_start(&m_power_timer, K_SECONDS(60), K_HOURS(12));

	return 0;
}

void app_work_sample(void)
{
	k_timer_start(&m_sample_timer, K_NO_WAIT, K_SECONDS(g_app_config.interval_sample));
}

void app_work_send(void)
{
	k_timer_start(&m_send_timer, K_NO_WAIT, K_FOREVER);
}

#if defined(CONFIG_SHIELD_CTR_Z)

static void backup_work_handler(struct k_work *work)
{
	int ret;

	ret = app_backup_sample();
	if (ret < 0) {
		LOG_ERR("Call `app_backup_sample` failed: %d", ret);
	}
}

static K_WORK_DEFINE(m_backup_work, backup_work_handler);

void app_work_backup_update(void)
{
	int ret;

	ret = k_work_submit_to_queue(&m_work_q, &m_backup_work);
	if (ret < 0) {
		LOG_ERR("Call `k_work_submit_to_queue` failed: %d", ret);
	}
}

#endif /* defined(CONFIG_SHIELD_CTR_Z) */
```
